# ATxmega128A1U device description
Architecture: AVR8_XMEGA; Family: AVR XMEGA
Registers are 8-bit, access not given, no defined reset value unless marked. A register's access mark holds for its fields unless they carry their own. Offsets are from the block's base; [hi:lo] are bit positions; {n}, {i} and the like mark numbered series; 'fields as' and 'values as' point back to an identical list.

## TC0 — 16-bit Timer/Counter 0
Instances: TCC0 0x800, TCD0 0x900, TCE0 0xA00, TCF0 0xB00
0x00 CTRLA — Control Register A
  [3:0] CLKSEL — Clock Selection
    0=OFF (Timer Off); 1=DIV1 (System Clock); 2=DIV2 (System Clock / 2); 3=DIV4 (System Clock / 4); 4=DIV8 (System Clock / 8); 5=DIV64 (System Clock / 64); 6=DIV256 (System Clock / 256); 7=DIV1024 (System Clock / 1024); {v}=EVCH{v-8} (Event Channel {v-8}) (v=8..15)
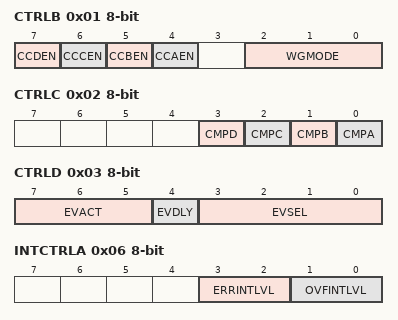
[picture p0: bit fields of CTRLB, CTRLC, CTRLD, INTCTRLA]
0x01 CTRLB — Control Register B
  [7] CCDEN — Compare or Capture D Enable
  [6] CCCEN — Compare or Capture C Enable
  [5] CCBEN — Compare or Capture B Enable
  [4] CCAEN — Compare or Capture A Enable
  [2:0] WGMODE — Waveform generation mode
    0=NORMAL (Normal Mode); 1=FRQ (Frequency Generation Mode); 3=SINGLESLOPE; 3=SS (Single Slope); 5=DSTOP (Dual Slope, Update on TOP); 5=DS_T (Dual Slope, Update on TOP); 6=DSBOTH (Dual Slope, Update on both TOP and BOTTOM); 6=DS_TB (Dual Slope, Update on both TOP and BOTTOM); 7=DSBOTTOM (Dual Slope, Update on BOTTOM); 7=DS_B (Dual Slope, Update on BOTTOM)
0x02 CTRLC — Control register C
  [3] CMPD — Compare D Output Value
  [2] CMPC — Compare C Output Value
  [1] CMPB — Compare B Output Value
  [0] CMPA — Compare A Output Value
0x03 CTRLD — Control Register D
  [7:5] EVACT — Event Action
    0=OFF (No Event Action); 1=CAPT (Input Capture); 2=UPDOWN (Externally Controlled Up/Down Count); 3=QDEC (Quadrature Decode); 4=RESTART; 5=FRQ (Frequency Capture); 6=PW (Pulse-width Capture)
  [4] EVDLY — Event Delay
  [3:0] EVSEL — Event Source Select
    0=OFF (No Event Source); {v}=CH{v-8} (Event Channel {v-8}) (v=8..15)
0x04 CTRLE — Control Register E
  [1:0] BYTEM — Byte Mode
    0=NORMAL (16-bit mode); 1=BYTEMODE (Timer/Counter operating in byte mode only); 2=SPLITMODE (Timer/Counter split into two 8-bit Counters (TC2))
0x06 INTCTRLA — Interrupt Control Register A
  [3:2] ERRINTLVL — Error Interrupt Level
    0=OFF (Interrupt Disabled); 1=LO (Low Level); 2=MED (Medium Level); 3=HI (High Level)
  [1:0] OVFINTLVL — Overflow interrupt level
    values as ERRINTLVL
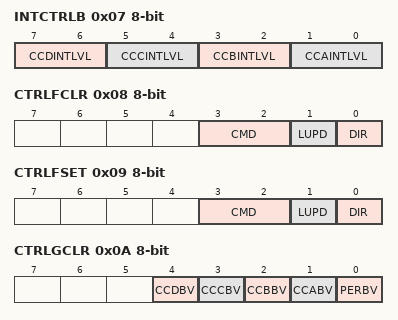
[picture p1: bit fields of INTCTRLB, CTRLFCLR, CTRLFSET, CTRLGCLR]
0x07 INTCTRLB — Interrupt Control Register B
  [all] fields
    values as INTCTRLA.ERRINTLVL
  [7:6] CCDINTLVL — Compare or Capture D Interrupt Level
  [5:4] CCCINTLVL — Compare or Capture C Interrupt Level
  [3:2] CCBINTLVL — Compare or Capture B Interrupt Level
  [1:0] CCAINTLVL — Compare or Capture A Interrupt Level
0x08 CTRLFCLR — Control Register F Clear
  [3:2] CMD — Command
  [1] LUPD — Lock Update
  [0] DIR — Direction
0x09 CTRLFSET — Control Register F Set
  [3:2] CMD — Command
    0=NONE (No Command); 1=UPDATE (Force Update); 2=RESTART (Force Restart); 3=RESET (Force Hard Reset)
  [1] LUPD — Lock Update
  [0] DIR — Direction
0x0A CTRLGCLR — Control Register G Clear
  [4] CCDBV — Compare or Capture D Buffer Valid
  [3] CCCBV — Compare or Capture C Buffer Valid
  [2] CCBBV — Compare or Capture B Buffer Valid
  [1] CCABV — Compare or Capture A Buffer Valid
  [0] PERBV — Period Buffer Valid
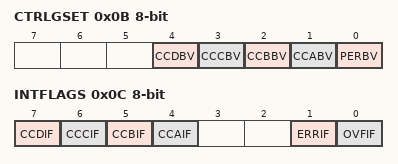
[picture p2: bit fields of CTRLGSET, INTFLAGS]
0x0B CTRLGSET — Control Register G Set
  fields as CTRLGCLR
0x0C INTFLAGS — Interrupt Flag Register
  [7] CCDIF — Compare or Capture D Interrupt Flag
  [6] CCCIF — Compare or Capture C Interrupt Flag
  [5] CCBIF — Compare or Capture B Interrupt Flag
  [4] CCAIF — Compare or Capture A Interrupt Flag
  [1] ERRIF — Error Interrupt Flag
  [0] OVFIF — Overflow Interrupt Flag
0x0F TEMP — Temporary Register For 16-bit Access
0x20 CNT 16-bit — Count
0x26 PER 16-bit — Period
0x28 CCA 16-bit — Compare or Capture A
0x2A CCB 16-bit — Compare or Capture B
0x2C CCC 16-bit — Compare or Capture C
0x2E CCD 16-bit — Compare or Capture D
0x36 PERBUF 16-bit — Period Buffer
0x38 CCABUF 16-bit — Compare Or Capture A Buffer
0x3A CCBBUF 16-bit — Compare Or Capture B Buffer
0x3C CCCBUF 16-bit — Compare Or Capture C Buffer
0x3E CCDBUF 16-bit — Compare Or Capture D Buffer

## TC1 — 16-bit Timer/Counter 1
Instances: TCC1 0x840, TCD1 0x940, TCE1 0xA40, TCF1 0xB40
Registers as TC0, without CCC, CCD, CCCBUF, CCDBUF; these are added or differ:
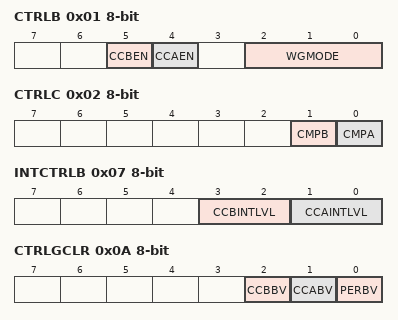
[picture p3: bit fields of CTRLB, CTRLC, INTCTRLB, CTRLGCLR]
0x01 CTRLB — Control Register B
  [5] CCBEN — Compare or Capture B Enable
  [4] CCAEN — Compare or Capture A Enable
  [2:0] WGMODE — Waveform generation mode
    values as TC0.CTRLB.WGMODE
0x02 CTRLC — Control register C
  [1] CMPB — Compare B Output Value
  [0] CMPA — Compare A Output Value
0x04 CTRLE — Control Register E
  [0] BYTEM — Byte Mode
0x07 INTCTRLB — Interrupt Control Register B
  [3:2] CCBINTLVL — Compare or Capture B Interrupt Level
    0=OFF (Interrupt Disabled); 1=LO (Low Level); 2=MED (Medium Level); 3=HI (High Level)
  [1:0] CCAINTLVL — Compare or Capture A Interrupt Level
    values as CCBINTLVL
0x0A CTRLGCLR — Control Register G Clear
  [2] CCBBV — Compare or Capture B Buffer Valid
  [1] CCABV — Compare or Capture A Buffer Valid
  [0] PERBV — Period Buffer Valid
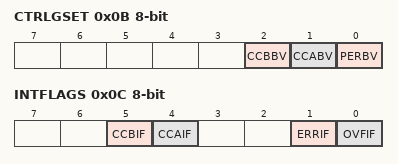
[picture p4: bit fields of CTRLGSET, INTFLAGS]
0x0B CTRLGSET — Control Register G Set
  fields as CTRLGCLR
0x0C INTFLAGS — Interrupt Flag Register
  [5] CCBIF — Compare or Capture B Interrupt Flag
  [4] CCAIF — Compare or Capture A Interrupt Flag
  [1] ERRIF — Error Interrupt Flag
  [0] OVFIF — Overflow Interrupt Flag
